AUTOSAR XML (schema 00046)
package /Software_Com_pkg
  sensor actuator sw component type Lidar_data_SWC1
    require port lidar_data_port: required-interface=Lidar_interface
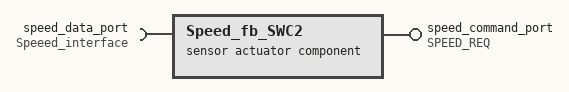
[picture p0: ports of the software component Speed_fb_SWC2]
  sensor actuator sw component type Speed_fb_SWC2
    provide port speed_command_port: provided-interface=SPEED_REQ
    require port speed_data_port: required-interface=Speeed_interface
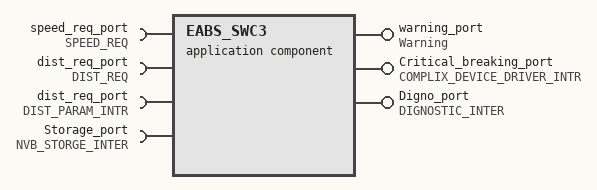
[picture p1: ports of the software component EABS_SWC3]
  application sw component type EABS_SWC3
    require port speed_req_port: required-interface=SPEED_REQ
    require port dist_req_port: required-interface=DIST_REQ
    provide port warning_port: provided-interface=Warning
    require port dist_req_port: required-interface=DIST_PARAM_INTR
    provide port Critical_breaking_port: provided-interface=COMPLIX_DEVICE_DRIVER_INTR
    require port Storage_port: required-interface=NVB_STORGE_INTER
    provide port Digno_port: provided-interface=DIGNOSTIC_INTER
  parameter sw component type param_SWC4
    provide port dist_procider_port: provided-interface=DIST_PARAM_INTR
  sensor actuator sw component type Led_Warinig_SWC5
    require port led_command_port: required-interface=Warning
  nv block sw component type Flash_NVB_SWC6
    provide port APP_command_port: provided-interface=NVB_STORGE_INTER
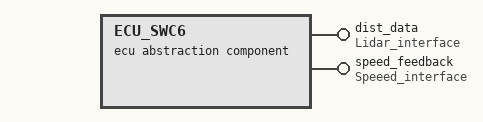
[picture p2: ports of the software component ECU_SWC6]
  ecu abstraction sw component type ECU_SWC6
    provide port dist_data: provided-interface=Lidar_interface
    provide port speed_feedback: provided-interface=Speeed_interface
  complex device driver sw component type CDD_SWC7
    require port Critical_breaking_port: required-interface=COMPLIX_DEVICE_DRIVER_INTR
  service sw component type Dign_SWC8
    require port DMS_port: required-interface=DIGNOSTIC_INTER
